# STM32F101_iown register map
Vendor: iown-homecontrol; Series: CM3; File version: 1.3
CPU: CM3 r1p1, little endian, no MPU, no FPU, VTOR, 4 interrupt priority bits
Registers are 32-bit, read-write, reset 0x0 unless marked. A register's access mark holds for its fields unless they carry their own. Offsets are from the block's base; [hi:lo] are bit positions; {n}, {i} and the like mark numbered series.

## OTG_FS_PWRCLK — USB on the go full speed
Base 0x50000E00
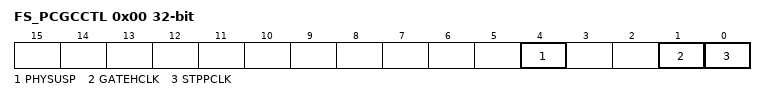
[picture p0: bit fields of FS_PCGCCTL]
0x00 FS_PCGCCTL — OTG_FS power and clock gating control register
  [4] PHYSUSP — PHY Suspended
  [1] GATEHCLK
  [0] STPPCLK — Stop PHY clock

## CAN1 — Controller area network
Base 0x40006400
Same registers: CAN2 0x40006800
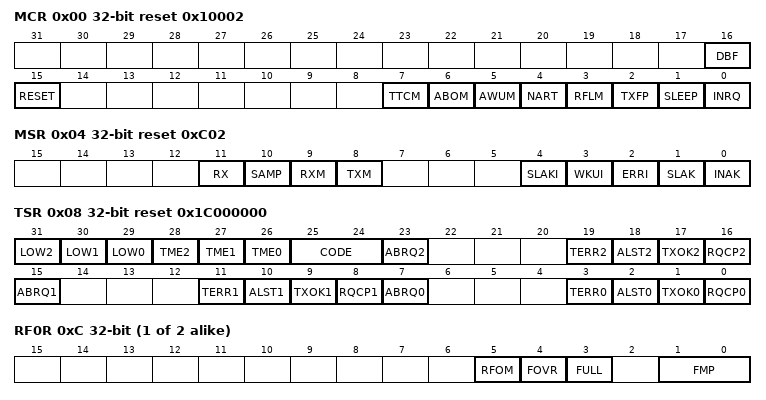
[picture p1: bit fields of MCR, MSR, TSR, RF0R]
0x00 MCR reset 0x10002 — master control register
  [16] DBF, [15] RESET, [7] TTCM, [6] ABOM, [5] AWUM, [4] NART, [3] RFLM, [2] TXFP, [1] SLEEP, [0] INRQ
0x04 MSR reset 0xC02 — master status register
  [11] RX ro, [10] SAMP ro, [9] RXM ro, [8] TXM ro, [4] SLAKI, [3] WKUI, [2] ERRI, [1] SLAK ro, [0] INAK ro
0x08 TSR reset 0x1C000000 — transmit status register
  [31] LOW2 ro — Lowest priority flag for mailbox 2
  [30] LOW1 ro — Lowest priority flag for mailbox 1
  [29] LOW0 ro — Lowest priority flag for mailbox 0
  [28] TME2 ro — Lowest priority flag for mailbox 2
  [27] TME1 ro — Lowest priority flag for mailbox 1
  [26] TME0 ro — Lowest priority flag for mailbox 0
  [25:24] CODE ro
  [23] ABRQ2
  [19] TERR2
  [18] ALST2
  [17] TXOK2
  [16] RQCP2
  [15] ABRQ1
  [11] TERR1
  [10] ALST1
  [9] TXOK1
  [8] RQCP1
  [7] ABRQ0
  [3] TERR0
  [2] ALST0
  [1] TXOK0
  [0] RQCP0
{0xC+4i} RF{i}R (i=0..1) — receive FIFO {i} register
  [5] RFOM — RFOM0
  [4] FOVR — FOVR0
  [3] FULL — FULL0
  [1:0] FMP ro — FMP0
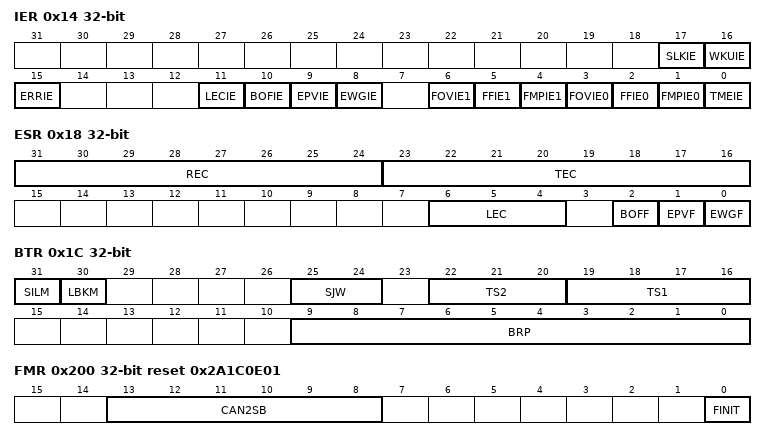
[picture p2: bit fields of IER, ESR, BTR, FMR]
0x14 IER — interrupt enable register
  [17] SLKIE, [16] WKUIE, [15] ERRIE, [11] LECIE, [10] BOFIE, [9] EPVIE, [8] EWGIE, [6] FOVIE1, [5] FFIE1, [4] FMPIE1, [3] FOVIE0, [2] FFIE0, [1] FMPIE0, [0] TMEIE
0x18 ESR — error status register
  [31:24] REC ro, [23:16] TEC ro, [6:4] LEC, [2] BOFF ro, [1] EPVF ro, [0] EWGF ro
0x1C BTR — bit timing register
  [31] SILM, [30] LBKM, [25:24] SJW, [22:20] TS2, [19:16] TS1, [9:0] BRP
0x200 FMR reset 0x2A1C0E01 — filter master register
  [13:8] CAN2SB, [0] FINIT
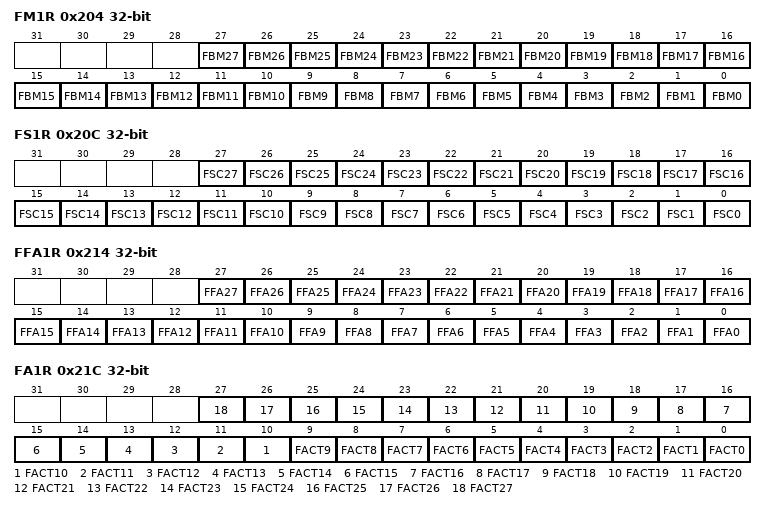
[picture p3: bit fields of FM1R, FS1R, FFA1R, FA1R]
0x204 FM1R — filter mode register
  [n] FBM{n} (n=0..27) — Filter mode
0x20C FS1R — filter scale register
  [n] FSC{n} (n=0..27) — Filter scale configuration
0x214 FFA1R — filter FIFO assignment register
  [n] FFA{n} (n=0..27) — Filter FIFO assignment for filter {n}
0x21C FA1R — filter activation register
  [n] FACT{n} (n=0..27) — Filter active

## Ethernet_MMC — Ethernet: MAC management counters
Base 0x40028100
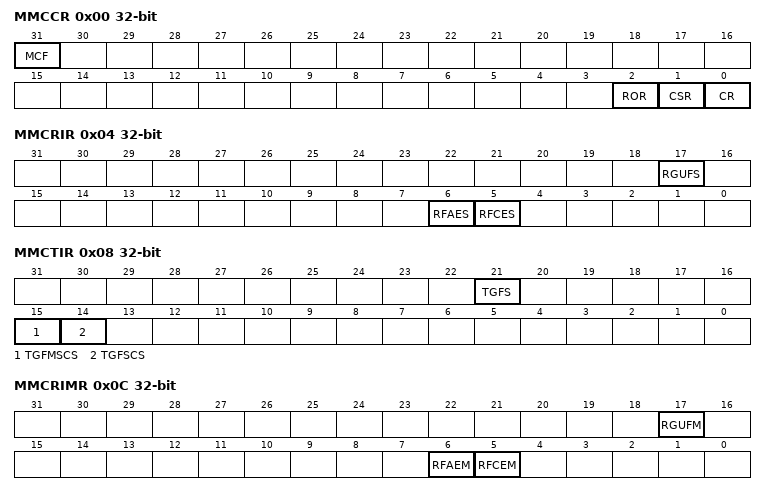
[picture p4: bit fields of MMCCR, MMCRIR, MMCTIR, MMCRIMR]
0x00 MMCCR — Ethernet MMC control register (ETH_MMCCR)
  [31] MCF — MMC counter freeze
  [2] ROR — Reset on read
  [1] CSR — Counter stop rollover
  [0] CR — Counter reset
0x04 MMCRIR — Ethernet MMC receive interrupt register (ETH_MMCRIR)
  [17] RGUFS — Received Good Unicast Frames Status
  [6] RFAES — Received frames alignment error status
  [5] RFCES — Received frames CRC error status
0x08 MMCTIR — Ethernet MMC transmit interrupt register (ETH_MMCTIR)
  [21] TGFS — Transmitted good frames status
  [15] TGFMSCS — Transmitted good frames more single collision status
  [14] TGFSCS — Transmitted good frames single collision status
0x0C MMCRIMR — Ethernet MMC receive interrupt mask register (ETH_MMCRIMR)
  [17] RGUFM — Received good unicast frames mask
  [6] RFAEM — Received frames alignment error mask
  [5] RFCEM — Received frame CRC error mask
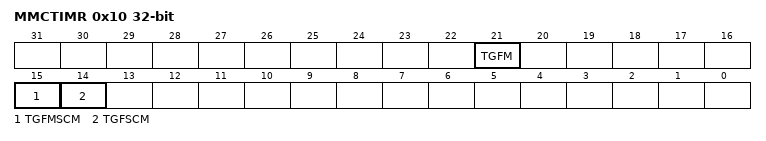
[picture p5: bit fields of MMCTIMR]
0x10 MMCTIMR — Ethernet MMC transmit interrupt mask register (ETH_MMCTIMR)
  [21] TGFM — Transmitted good frames mask
  [15] TGFMSCM — Transmitted good frames more single collision mask
  [14] TGFSCM — Transmitted good frames single collision mask
0x4C MMCTGFSCCR ro — Ethernet MMC transmitted good frames after a single collision counter
  [31:0] TGFSCC — Transmitted good frames after a single collision counter
0x50 MMCTGFMSCCR ro — Ethernet MMC transmitted good frames after more than a single collision
  [31:0] TGFMSCC — Transmitted good frames after more than a single collision counter
0x68 MMCTGFCR ro — Ethernet MMC transmitted good frames counter register
  [31:0] TGFC — Transmitted good frames counter
0x94 MMCRFCECR ro — Ethernet MMC received frames with CRC error counter register
  [31:0] RFCFC — Received frames with CRC error counter
0x98 MMCRFAECR ro — Ethernet MMC received frames with alignment error counter register
  [31:0] RFAEC — Received frames with alignment error counter
0xC4 MMCRGUFCR ro — MMC received good unicast frames counter register
  [31:0] RGUFC — Received good unicast frames counter
